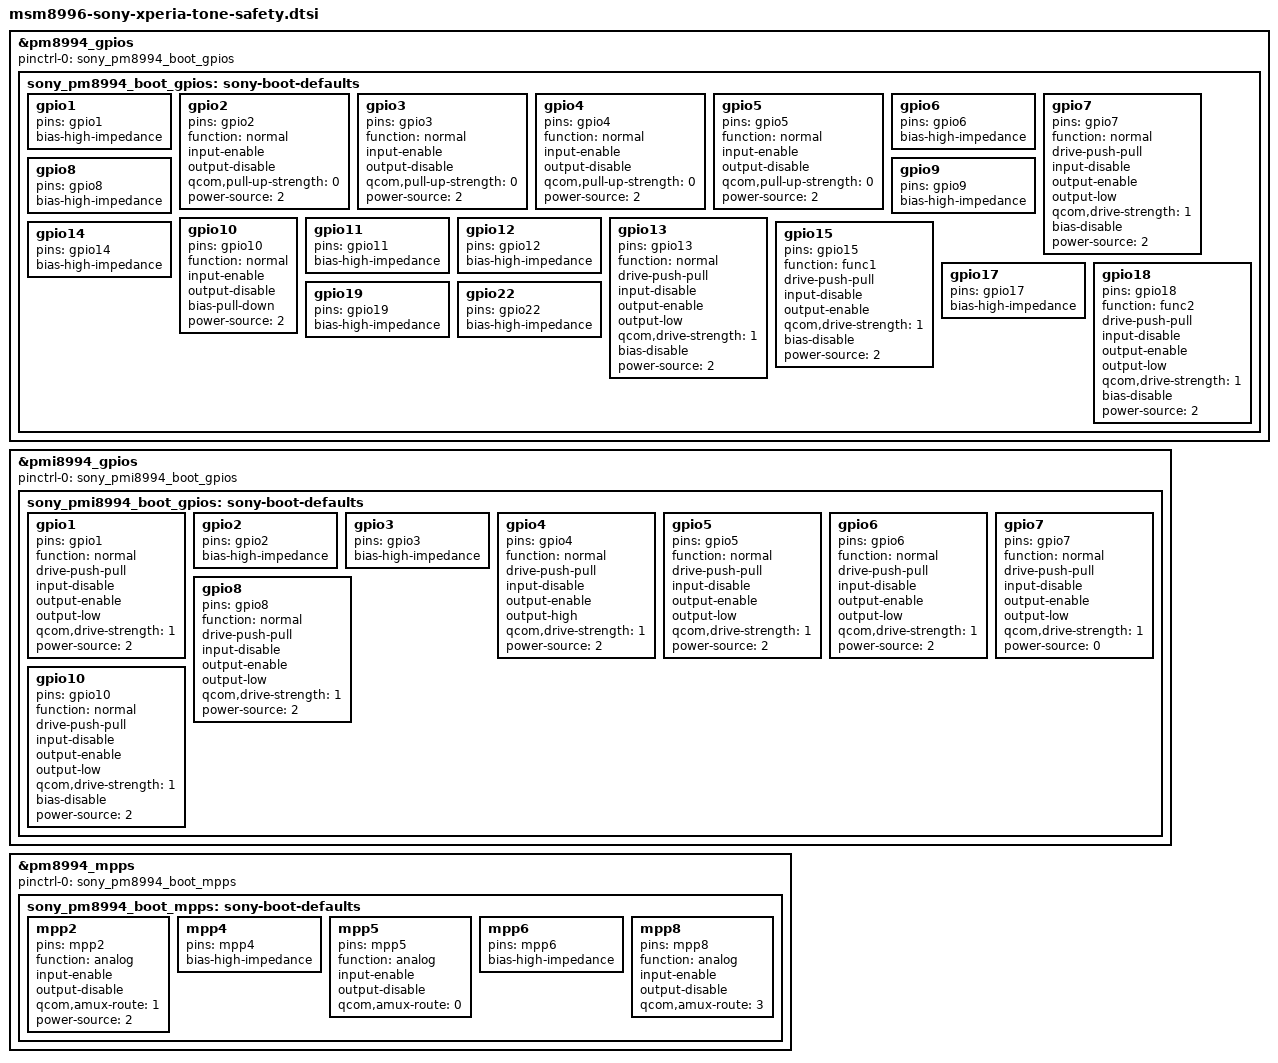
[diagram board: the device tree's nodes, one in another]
// SPDX-License-Identifier: GPL-2.0-only
/*
 * Sony Dora PMIC boot pin states, normalized from final Sony4.4 DT.
 * Reference: 0c295b15b6d0fb59a64e13b9e0ef2070818ef2a1.
 * Copyright (c) 2014-2015 The Linux Foundation. All rights reserved.
 * Copyright (C) 2014 Sony Mobile Communications Inc.
 *
 * Include after Tone. Apply only explicit original settings; do not program
 * disabled/unconfigured pins or synthesize USB ID/DPDM/charger ownership.
 */

&pm8994_gpios {
	pinctrl-names = "default";
	pinctrl-0 = <&sony_pm8994_boot_gpios>;

	sony_pm8994_boot_gpios: sony-boot-defaults {
		gpio1 {
			pins = "gpio1";
			bias-high-impedance;
		};

		gpio2 {
			pins = "gpio2";
			function = "normal";
			input-enable;
			output-disable;
			qcom,pull-up-strength = <0>;
			power-source = <2>;
		};

		gpio3 {
			pins = "gpio3";
			function = "normal";
			input-enable;
			output-disable;
			qcom,pull-up-strength = <0>;
			power-source = <2>;
		};

		gpio4 {
			pins = "gpio4";
			function = "normal";
			input-enable;
			output-disable;
			qcom,pull-up-strength = <0>;
			power-source = <2>;
		};

		gpio5 {
			pins = "gpio5";
			function = "normal";
			input-enable;
			output-disable;
			qcom,pull-up-strength = <0>;
			power-source = <2>;
		};

		gpio6 {
			pins = "gpio6";
			bias-high-impedance;
		};

		gpio7 {
			pins = "gpio7";
			function = "normal";
			drive-push-pull;
			input-disable;
			output-enable;
			output-low;
			qcom,drive-strength = <1>;
			bias-disable;
			power-source = <2>;
		};

		gpio8 {
			pins = "gpio8";
			bias-high-impedance;
		};

		gpio9 {
			pins = "gpio9";
			bias-high-impedance;
		};

		gpio10 {
			pins = "gpio10";
			function = "normal";
			input-enable;
			output-disable;
			bias-pull-down;
			power-source = <2>;
		};

		gpio11 {
			pins = "gpio11";
			bias-high-impedance;
		};

		gpio12 {
			pins = "gpio12";
			bias-high-impedance;
		};

		gpio13 {
			pins = "gpio13";
			function = "normal";
			drive-push-pull;
			input-disable;
			output-enable;
			output-low;
			qcom,drive-strength = <1>;
			bias-disable;
			power-source = <2>;
		};

		gpio14 {
			pins = "gpio14";
			bias-high-impedance;
		};

		gpio15 {
			pins = "gpio15";
			function = "func1";
			drive-push-pull;
			input-disable;
			output-enable;
			qcom,drive-strength = <1>;
			bias-disable;
			power-source = <2>;
		};

		gpio17 {
			pins = "gpio17";
			bias-high-impedance;
		};

		gpio18 {
			pins = "gpio18";
			function = "func2";
			drive-push-pull;
			input-disable;
			output-enable;
			output-low;
			qcom,drive-strength = <1>;
			bias-disable;
			power-source = <2>;
		};

		gpio19 {
			pins = "gpio19";
			bias-high-impedance;
		};

		gpio22 {
			pins = "gpio22";
			bias-high-impedance;
		};

	};
};

&pmi8994_gpios {
	pinctrl-names = "default";
	pinctrl-0 = <&sony_pmi8994_boot_gpios>;

	sony_pmi8994_boot_gpios: sony-boot-defaults {
		gpio1 {
			pins = "gpio1";
			function = "normal";
			drive-push-pull;
			input-disable;
			output-enable;
			output-low;
			qcom,drive-strength = <1>;
			power-source = <2>;
		};

		gpio2 {
			pins = "gpio2";
			bias-high-impedance;
		};

		gpio3 {
			pins = "gpio3";
			bias-high-impedance;
		};

		gpio4 {
			pins = "gpio4";
			function = "normal";
			drive-push-pull;
			input-disable;
			output-enable;
			output-high;
			qcom,drive-strength = <1>;
			power-source = <2>;
		};

		gpio5 {
			pins = "gpio5";
			function = "normal";
			drive-push-pull;
			input-disable;
			output-enable;
			output-low;
			qcom,drive-strength = <1>;
			power-source = <2>;
		};

		gpio6 {
			pins = "gpio6";
			function = "normal";
			drive-push-pull;
			input-disable;
			output-enable;
			output-low;
			qcom,drive-strength = <1>;
			power-source = <2>;
		};

		gpio7 {
			pins = "gpio7";
			function = "normal";
			drive-push-pull;
			input-disable;
			output-enable;
			output-low;
			qcom,drive-strength = <1>;
			power-source = <0>;
		};

		gpio8 {
			pins = "gpio8";
			function = "normal";
			drive-push-pull;
			input-disable;
			output-enable;
			output-low;
			qcom,drive-strength = <1>;
			power-source = <2>;
		};

		gpio10 {
			pins = "gpio10";
			function = "normal";
			drive-push-pull;
			input-disable;
			output-enable;
			output-low;
			qcom,drive-strength = <1>;
			bias-disable;
			power-source = <2>;
		};

	};
};

&pm8994_mpps {
	pinctrl-names = "default";
	pinctrl-0 = <&sony_pm8994_boot_mpps>;

	sony_pm8994_boot_mpps: sony-boot-defaults {
		mpp2 {
			pins = "mpp2";
			function = "analog";
			input-enable;
			output-disable;
			qcom,amux-route = <1>;
			power-source = <2>;
		};

		mpp4 {
			pins = "mpp4";
			bias-high-impedance;
		};

		mpp5 {
			pins = "mpp5";
			function = "analog";
			input-enable;
			output-disable;
			qcom,amux-route = <0>;
		};

		mpp6 {
			pins = "mpp6";
			bias-high-impedance;
		};

		mpp8 {
			pins = "mpp8";
			function = "analog";
			input-enable;
			output-disable;
			qcom,amux-route = <3>;
		};

	};
};

